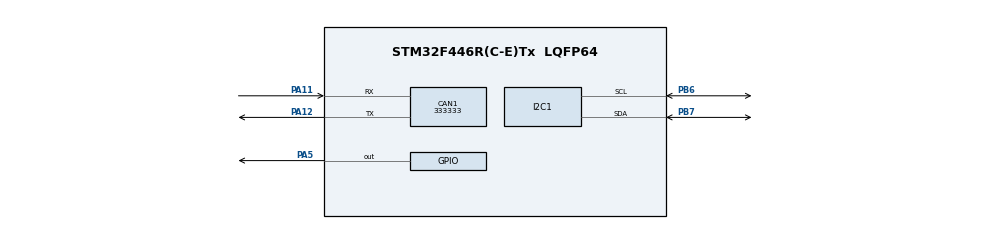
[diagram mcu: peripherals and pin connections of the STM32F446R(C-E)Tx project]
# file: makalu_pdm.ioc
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CAN1.CalculateBaudRate=333333
CAN1.CalculateTimeBit=3000
CAN1.CalculateTimeQuantum=1000.0
FREERTOS.Tasks01=defaultTask,24,128,StartDefaultTask,Default,NULL,Dynamic,NULL,NULL
FREERTOS.configCHECK_FOR_STACK_OVERFLOW=0
FREERTOS.configTOTAL_HEAP_SIZE=16384
Mcu.Family=STM32F4
Mcu.Name=STM32F446R(C-E)Tx
Mcu.Package=LQFP64
NVIC.CAN1_RX0_IRQn=true\:5\:0\:false\:false\:true\:true\:true\:true\:true
NVIC.PriorityGroup=NVIC_PRIORITYGROUP_4
NVIC.TIM6_DAC_IRQn=true\:15\:0\:false\:false\:true\:false\:false\:true\:true
NVIC.TimeBase=TIM6_DAC_IRQn
NVIC.TimeBaseIP=TIM6
PA11.Mode=CAN_Activate
PA11.Signal=CAN1_RX
PA12.Mode=CAN_Activate
PA12.Signal=CAN1_TX
PA13.Mode=Trace_Asynchronous_SW
PA13.Signal=SYS_JTMS-SWDIO
PA14.Mode=Trace_Asynchronous_SW
PA14.Signal=SYS_JTCK-SWCLK
PA5.Signal=GPIO_Output
PB3.Mode=Trace_Asynchronous_SW
PB3.Signal=SYS_JTDO-SWO
PB6.Mode=I2C
PB6.Signal=I2C1_SCL
PB7.Mode=I2C
PB7.Signal=I2C1_SDA
ProjectManager.HeapSize=0x200
ProjectManager.StackSize=0x400
ProjectManager.TargetToolchain=CMake
RCC.CortexFreq_Value=16000000
RCC.USBFreq_Value=96000000
RCC.VCOOutputFreq_Value=192000000
VP_FREERTOS_VS_CMSIS_V2.Mode=CMSIS_V2
VP_SYS_VS_tim6.Mode=TIM6
board=custom

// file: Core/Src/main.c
/* USER CODE BEGIN Header */
/**
  ******************************************************************************
  * @file           : main.c
  * @brief          : Main program body
  *                   Board  : NUCLEO-F446RE
  *                   CAN1   : PA11 = RX  /  PA12 = TX  (AF9)
  *                   Timing : HSI 16 MHz, no PLL
  *                            Prescaler=4, BS1=5TQ, BS2=2TQ → 500 kbps
  *                            Sample point = (1+5)/8 = 75 %
  ******************************************************************************
  */
/* USER CODE END Header */
#include "main.h"
#include "cmsis_os.h"

/* USER CODE BEGIN Includes */
#include "main_app.h"
#include "makalu_bxcan.h"
#include "default_task.h"
/* USER CODE END Includes */

CAN_HandleTypeDef hcan1;

I2C_HandleTypeDef hi2c1;

/* Definitions for defaultTask */
osThreadId_t defaultTaskHandle;
const osThreadAttr_t defaultTask_attributes = {
  .name = "defaultTask",
  .stack_size = 128 * 4,
  .priority = (osPriority_t) osPriorityNormal,
};

void SystemClock_Config(void);
static void MX_GPIO_Init(void);
static void MX_CAN1_Init(void);
static void MX_I2C1_Init(void);

/* USER CODE BEGIN 0 */

int main(void)
{

  /* MCU Configuration--------------------------------------------------------*/

  /* Reset of all peripherals, Initializes the Flash interface and the Systick. */
  HAL_Init();

  /* Configure the system clock */
  SystemClock_Config();

  /* Initialize all configured peripherals */
  MX_GPIO_Init();
  MX_CAN1_Init();
  MX_I2C1_Init();

  /* Init scheduler */
  osKernelInitialize();

  /* Create the thread(s) */
  /* creation of defaultTask */

  defaultTaskHandle = osThreadNew(StartDefaultTask, NULL, &defaultTask_attributes);

  /* Start scheduler */
  osKernelStart();

  /* We should never get here as control is now taken by the scheduler */

  /* Infinite loop */
  while (1) {

  }
}

void SystemClock_Config(void)
{
  RCC_OscInitTypeDef RCC_OscInitStruct = {0};
  RCC_ClkInitTypeDef RCC_ClkInitStruct = {0};

  /** Configure the main internal regulator output voltage
  */
  __HAL_RCC_PWR_CLK_ENABLE();
  __HAL_PWR_VOLTAGESCALING_CONFIG(PWR_REGULATOR_VOLTAGE_SCALE3);

  /** Initializes the RCC Oscillators according to the specified parameters
  * in the RCC_OscInitTypeDef structure.
  */
  RCC_OscInitStruct.OscillatorType = RCC_OSCILLATORTYPE_HSI;
  RCC_OscInitStruct.HSIState = RCC_HSI_ON;
  RCC_OscInitStruct.HSICalibrationValue = RCC_HSICALIBRATION_DEFAULT;
  RCC_OscInitStruct.PLL.PLLState = RCC_PLL_NONE;
  if (HAL_RCC_OscConfig(&RCC_OscInitStruct) != HAL_OK)
  {
    Error_Handler();
  }

  /** Initializes the CPU, AHB and APB buses clocks
  */
  RCC_ClkInitStruct.ClockType = RCC_CLOCKTYPE_HCLK|RCC_CLOCKTYPE_SYSCLK
                              |RCC_CLOCKTYPE_PCLK1|RCC_CLOCKTYPE_PCLK2;
  RCC_ClkInitStruct.SYSCLKSource = RCC_SYSCLKSOURCE_HSI;
  RCC_ClkInitStruct.AHBCLKDivider = RCC_SYSCLK_DIV1;
  RCC_ClkInitStruct.APB1CLKDivider = RCC_HCLK_DIV1;
  RCC_ClkInitStruct.APB2CLKDivider = RCC_HCLK_DIV1;

  if (HAL_RCC_ClockConfig(&RCC_ClkInitStruct, FLASH_LATENCY_0) != HAL_OK)
  {
    Error_Handler();
  }
}

static void MX_CAN1_Init(void)
{

  hcan1.Instance = CAN1;
  hcan1.Init.Prescaler = 4;
  hcan1.Init.Mode = CAN_MODE_NORMAL;
  hcan1.Init.SyncJumpWidth = CAN_SJW_1TQ;
  hcan1.Init.TimeSeg1 = CAN_BS1_5TQ;
  hcan1.Init.TimeSeg2 = CAN_BS2_2TQ;
  hcan1.Init.TimeTriggeredMode = DISABLE;
  hcan1.Init.AutoBusOff = DISABLE;
  hcan1.Init.AutoWakeUp = DISABLE;
  hcan1.Init.AutoRetransmission = DISABLE;
  hcan1.Init.ReceiveFifoLocked = DISABLE;
  hcan1.Init.TransmitFifoPriority = DISABLE;
  if (HAL_CAN_Init(&hcan1) != HAL_OK)
  {
    Error_Handler();
  }

}

static void MX_I2C1_Init(void)
{

  hi2c1.Instance = I2C1;
  hi2c1.Init.ClockSpeed = 100000;
  hi2c1.Init.DutyCycle = I2C_DUTYCYCLE_2;
  hi2c1.Init.OwnAddress1 = 0;
  hi2c1.Init.AddressingMode = I2C_ADDRESSINGMODE_7BIT;
  hi2c1.Init.DualAddressMode = I2C_DUALADDRESS_DISABLE;
  hi2c1.Init.OwnAddress2 = 0;
  hi2c1.Init.GeneralCallMode = I2C_GENERALCALL_DISABLE;
  hi2c1.Init.NoStretchMode = I2C_NOSTRETCH_DISABLE;
  if (HAL_I2C_Init(&hi2c1) != HAL_OK)
  {
    Error_Handler();
  }

}

static void MX_GPIO_Init(void)
{
  GPIO_InitTypeDef GPIO_InitStruct = {0};

  /* GPIO Ports Clock Enable */
  __HAL_RCC_GPIOA_CLK_ENABLE();
  __HAL_RCC_GPIOB_CLK_ENABLE();

  /*Configure GPIO pin Output Level */
  HAL_GPIO_WritePin(GPIOA, GPIO_PIN_5, GPIO_PIN_RESET);

  /*Configure GPIO pin : PA5 */
  GPIO_InitStruct.Pin = GPIO_PIN_5;
  GPIO_InitStruct.Mode = GPIO_MODE_OUTPUT_PP;
  GPIO_InitStruct.Pull = GPIO_NOPULL;
  GPIO_InitStruct.Speed = GPIO_SPEED_FREQ_LOW;
  HAL_GPIO_Init(GPIOA, &GPIO_InitStruct);

}

/* USER CODE BEGIN 4 */

void HAL_CAN_RxFifo0MsgPendingCallback(CAN_HandleTypeDef *hcan)
{

  makalu_bxcan_rx_isr();
}

/* USER CODE END 4 */

/* USER CODE BEGIN Header_StartDefaultTask */

void HAL_TIM_PeriodElapsedCallback(TIM_HandleTypeDef *htim)
{
  if (htim->Instance == TIM6)
  {
    HAL_IncTick();
  }
}

void Error_Handler(void)
{
  __disable_irq();
  while (1)
  {
  }
}
